AUTOSAR XML (schema 4-2-1)
package /ComponentTypes
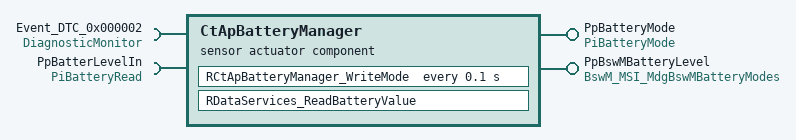
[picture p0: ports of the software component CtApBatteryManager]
  sensor actuator sw component type CtApBatteryManager
    provide port PpBatteryMode: mode-switch-sender-com-spec{enhanced-mode-api=false, mode-group=BatteryModes, queue-length=1}, provided-interface=PiBatteryMode
    provide port PpBswMBatteryLevel: mode-switch-sender-com-spec{enhanced-mode-api=false, mode-group=BswM_MDGP_MdgBswMBatteryModes, queue-length=1}, provided-interface=BswM_MSI_MdgBswMBatteryModes
    require port Event_DTC_0x000002: required-interface=DiagnosticMonitor
    require port PpBatterLevelIn: required-interface=PiBatteryRead
    behavior CtApBatteryManager_InternalBehavior: data-type-mapping=ApMappingSet
      timing event TMT_RCtApBatteryManager: start-on-event=RCtApBatteryManager_WriteMode, period=0.1
      runnable RCtApBatteryManager_WriteMode: symbol=RCtApBatteryManager
        mode switch point SWITCH_PpBatteryMode_BatteryModes: mode-group=PpBatteryMode.BatteryModes
        mode switch point SWITCH_PpBswMBatteryLevel_BswM_MDGP_MdgBswMBatteryModes: mode-group=PpBswMBatteryLevel.BswM_MDGP_MdgBswMBatteryModes
        sync call SC_Event_DTC_0x000002_SetEventStatus: operation=Event_DTC_0x000002.SetEventStatus, timeout=0
      runnable RDataServices_ReadBatteryValue: symbol=DataServices_BatteryValue_ReadData
        asynchronous server call result point ASCRP_RDataServices_ReadBatteryValue_AC_PpBatterLevelIn_ReadBatteryLevel: asynchronous-server-call-point=AC_PpBatterLevelIn_ReadBatteryLevel
        async call AC_PpBatterLevelIn_ReadBatteryLevel: operation=PpBatterLevelIn.ReadBatteryLevel
  swc implementation CtApBatteryManager_Implementation: behavior=CtApBatteryManager_InternalBehavior
    code-descriptors:
      code Default: artifact-descriptors=autosar-engineering-object={short-label=Default, category=SWSRC}
